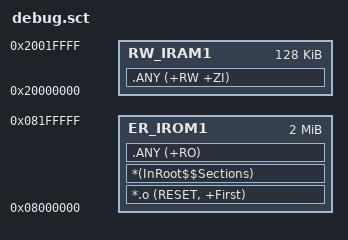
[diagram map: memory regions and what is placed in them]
; armfly-v7 scatter file for STM32H743XIH6

LR_IROM1 0x08000000 0x00200000  {
  ER_IROM1 0x08000000 0x00200000  {
   *.o (RESET, +First)
   *(InRoot$$Sections)
   .ANY (+RO)
  }

  RW_IRAM1 0x20000000 0x00020000  {
   .ANY (+RW +ZI)
  }
}
